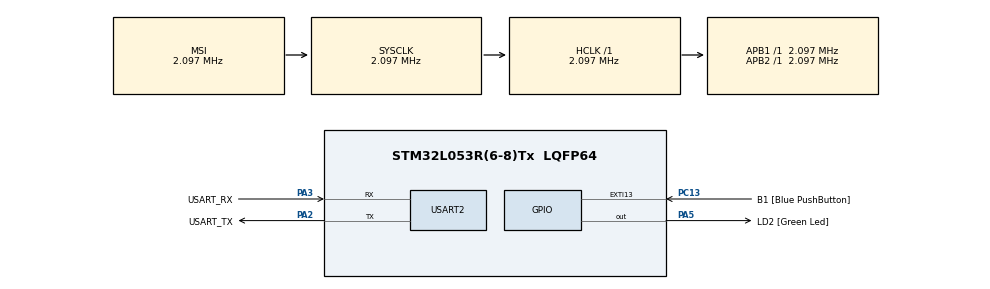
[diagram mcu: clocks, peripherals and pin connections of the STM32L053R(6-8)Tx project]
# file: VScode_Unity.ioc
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Mcu.Family=STM32L0
Mcu.Name=STM32L053R(6-8)Tx
Mcu.Package=LQFP64
NVIC.USART2_IRQn=true\:0\:0\:false\:false\:true\:true\:true\:true
PA13.GPIO_Label=TMS
PA13.Mode=Serial_Wire
PA13.Signal=SYS_SWDIO
PA14.GPIO_Label=TCK
PA14.Mode=Serial_Wire
PA14.Signal=SYS_SWCLK
PA2.GPIO_Label=USART_TX
PA2.Mode=Asynchronous
PA2.Signal=USART2_TX
PA3.GPIO_Label=USART_RX
PA3.Mode=Asynchronous
PA3.Signal=USART2_RX
PA5.GPIO_Label=LD2 [Green Led]
PA5.Signal=GPIO_Output
PC13.GPIO_Label=B1 [Blue PushButton]
PC13.GPIO_ModeDefaultEXTI=GPIO_MODE_IT_FALLING
PC13.Signal=GPXTI13
PC14-OSC32_IN.Mode=LSE-External-Oscillator
PC14-OSC32_IN.Signal=RCC_OSC32_IN
PC15-OSC32_OUT.Mode=LSE-External-Oscillator
PC15-OSC32_OUT.Signal=RCC_OSC32_OUT
PH0-OSC_IN.Mode=HSE-External-Clock-Source
PH0-OSC_IN.Signal=RCC_OSC_IN
PH1-OSC_OUT.Signal=RCC_OSC_OUT
ProjectManager.HeapSize=0x200
ProjectManager.StackSize=0x400
ProjectManager.TargetToolchain=Makefile
RCC.AHBFreq_Value=2097000
RCC.APB1Freq_Value=2097000
RCC.APB1TimFreq_Value=2097000
RCC.APB2Freq_Value=2097000
RCC.APB2TimFreq_Value=2097000
RCC.HSE_VALUE=8000000
RCC.HSI16_VALUE=16000000
RCC.HSI48_VALUE=48000000
RCC.HSI_VALUE=16000000
RCC.MSI_VALUE=2097000
RCC.SYSCLKFreq_VALUE=2097000
RCC.VCOOutputFreq_Value=48000000
USART2.VirtualMode-Asynchronous=VM_ASYNC
board=NUCLEO-L053R8

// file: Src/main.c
/* USER CODE BEGIN Header */
/**
  ******************************************************************************
  * @file           : main.c
  * @brief          : Main program body
  ******************************************************************************
  * @attention
  *
  * Copyright (c) 2024 STMicroelectronics.
  * All rights reserved.
  *
  * This software is licensed under terms that can be found in the LICENSE file
  * in the root directory of this software component.
  * If no LICENSE file comes with this software, it is provided AS-IS.
  *
  ******************************************************************************
  */
/* USER CODE END Header */
#include "main.h"
#include "usart.h"
#include "gpio.h"

/* USER CODE BEGIN Includes */
#include "debugPrintf.h"
#include "console.h"
/* USER CODE END Includes */

void SystemClock_Config(void);

int main(void)
{

  /* MCU Configuration--------------------------------------------------------*/

  /* Reset of all peripherals, Initializes the Flash interface and the Systick. */
  HAL_Init();

  /* Configure the system clock */
  SystemClock_Config();

  /* Initialize all configured peripherals */
  MX_GPIO_Init();
  MX_USART2_UART_Init();
  /* USER CODE BEGIN 2 */
  debug_init();
  /* USER CODE END 2 */
  dbg_printf_ln("Starting console ...");
  /* Infinite loop */
  while (1)
  {
    console_loop();
    // dbg_printf_ln("Hello there %d\n", 121314);
    // HAL_GPIO_TogglePin(LD2_GPIO_Port,LD2_Pin);
    // HAL_Delay(5000);
  }
}

void SystemClock_Config(void)
{
  RCC_OscInitTypeDef RCC_OscInitStruct = {0};
  RCC_ClkInitTypeDef RCC_ClkInitStruct = {0};
  RCC_PeriphCLKInitTypeDef PeriphClkInit = {0};

  /** Configure the main internal regulator output voltage
  */
  __HAL_PWR_VOLTAGESCALING_CONFIG(PWR_REGULATOR_VOLTAGE_SCALE1);

  /** Initializes the RCC Oscillators according to the specified parameters
  * in the RCC_OscInitTypeDef structure.
  */
  RCC_OscInitStruct.OscillatorType = RCC_OSCILLATORTYPE_MSI;
  RCC_OscInitStruct.MSIState = RCC_MSI_ON;
  RCC_OscInitStruct.MSICalibrationValue = 0;
  RCC_OscInitStruct.MSIClockRange = RCC_MSIRANGE_5;
  RCC_OscInitStruct.PLL.PLLState = RCC_PLL_NONE;
  if (HAL_RCC_OscConfig(&RCC_OscInitStruct) != HAL_OK)
  {
    Error_Handler();
  }

  /** Initializes the CPU, AHB and APB buses clocks
  */
  RCC_ClkInitStruct.ClockType = RCC_CLOCKTYPE_HCLK|RCC_CLOCKTYPE_SYSCLK
                              |RCC_CLOCKTYPE_PCLK1|RCC_CLOCKTYPE_PCLK2;
  RCC_ClkInitStruct.SYSCLKSource = RCC_SYSCLKSOURCE_MSI;
  RCC_ClkInitStruct.AHBCLKDivider = RCC_SYSCLK_DIV1;
  RCC_ClkInitStruct.APB1CLKDivider = RCC_HCLK_DIV1;
  RCC_ClkInitStruct.APB2CLKDivider = RCC_HCLK_DIV1;

  if (HAL_RCC_ClockConfig(&RCC_ClkInitStruct, FLASH_LATENCY_0) != HAL_OK)
  {
    Error_Handler();
  }
  PeriphClkInit.PeriphClockSelection = RCC_PERIPHCLK_USART2;
  PeriphClkInit.Usart2ClockSelection = RCC_USART2CLKSOURCE_PCLK1;
  if (HAL_RCCEx_PeriphCLKConfig(&PeriphClkInit) != HAL_OK)
  {
    Error_Handler();
  }
}

void Error_Handler(void)
{
  __disable_irq();
  while (1)
  {
  }
}
